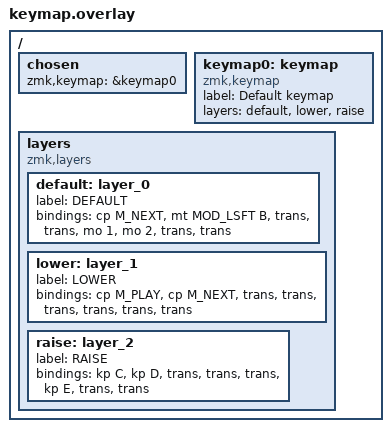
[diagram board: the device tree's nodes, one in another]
#include <dt-bindings/zmk/keys.h>
#include <behaviors.dtsi>

/ {
	chosen {
		zmk,keymap = &keymap0;
	};

	keymap0: keymap {
		compatible = "zmk,keymap";
		label ="Default keymap";
		layers = <&default &lower &raise>;
	};

	layers {
		compatible = "zmk,layers";

		default: layer_0 {
			label = "DEFAULT";
			bindings = <
				&cp M_NEXT &mt MOD_LSFT B &trans &trans
				&mo 1  &mo 2         &trans &trans>;
		};

		lower: layer_1 {
			label = "LOWER";

			bindings = <
				&cp M_PLAY &cp M_NEXT &trans &trans
				&trans  &trans &trans &trans>;
		};

		raise: layer_2 {
			label = "RAISE";
			bindings = <
				&kp C &kp D &trans &trans
				&trans  &kp E &trans &trans>;
		};
	};
};
